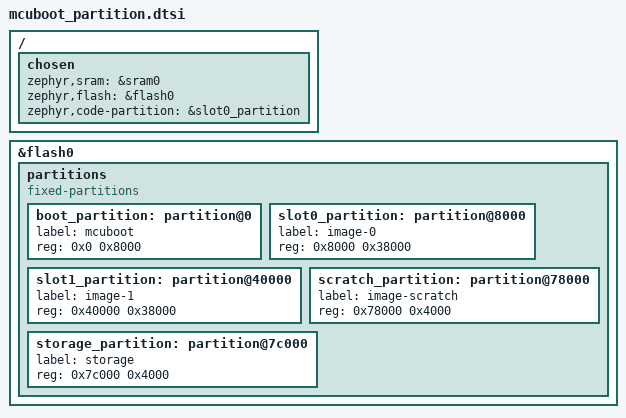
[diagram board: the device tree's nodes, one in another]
/*
 * Copyright (c) 2024 Jacob Winther
 *
 * SPDX-License-Identifier: Apache-2.0
 */

/ {
	chosen {
		zephyr,sram = &sram0;
		zephyr,flash = &flash0;
		zephyr,code-partition = &slot0_partition;
	};
};
&flash0 {
	partitions {
		compatible = "fixed-partitions";
		#address-cells = <1>;
		#size-cells = <1>;

		boot_partition: partition@0 {
			label = "mcuboot";
			reg = <0x0 0x8000>;
		};
		slot0_partition: partition@8000 {
			label = "image-0";
			reg = <0x8000 0x38000>;
		};
		slot1_partition: partition@40000 {
			label = "image-1";
			reg = <0x40000 0x38000>;
		};
		scratch_partition: partition@78000 {
			label = "image-scratch";
			reg = <0x78000 0x4000>;
		};
		storage_partition: partition@7c000 {
			label = "storage";
			reg = <0x7c000 0x4000>;
		};
	};
};
